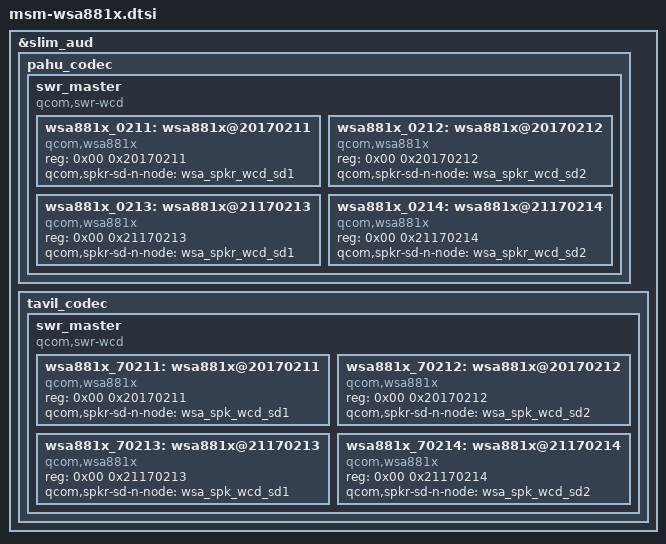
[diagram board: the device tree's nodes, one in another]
// SPDX-License-Identifier: GPL-2.0-only
/*
 * Copyright (c) 2016-2017, The Linux Foundation. All rights reserved.
 */

&slim_aud {
	pahu_codec {
		swr_master {
			compatible = "qcom,swr-wcd";
			#address-cells = <2>;
			#size-cells = <0>;

			wsa881x_0211: wsa881x@20170211 {
				compatible = "qcom,wsa881x";
				reg = <0x00 0x20170211>;
				qcom,spkr-sd-n-node = <&wsa_spkr_wcd_sd1>;
			};

			wsa881x_0212: wsa881x@20170212 {
				compatible = "qcom,wsa881x";
				reg = <0x00 0x20170212>;
				qcom,spkr-sd-n-node = <&wsa_spkr_wcd_sd2>;
			};

			wsa881x_0213: wsa881x@21170213 {
				compatible = "qcom,wsa881x";
				reg = <0x00 0x21170213>;
				qcom,spkr-sd-n-node = <&wsa_spkr_wcd_sd1>;
			};

			wsa881x_0214: wsa881x@21170214 {
				compatible = "qcom,wsa881x";
				reg = <0x00 0x21170214>;
				qcom,spkr-sd-n-node = <&wsa_spkr_wcd_sd2>;
			};
		};
	};

	tavil_codec {
		swr_master {
			compatible = "qcom,swr-wcd";
			#address-cells = <2>;
			#size-cells = <0>;

			wsa881x_70211: wsa881x@20170211 {
				compatible = "qcom,wsa881x";
				reg = <0x00 0x20170211>;
				qcom,spkr-sd-n-node = <&wsa_spk_wcd_sd1>;
			};

			wsa881x_70212: wsa881x@20170212 {
				compatible = "qcom,wsa881x";
				reg = <0x00 0x20170212>;
				qcom,spkr-sd-n-node = <&wsa_spk_wcd_sd2>;
			};

			wsa881x_70213: wsa881x@21170213 {
				compatible = "qcom,wsa881x";
				reg = <0x00 0x21170213>;
				qcom,spkr-sd-n-node = <&wsa_spk_wcd_sd1>;
			};

			wsa881x_70214: wsa881x@21170214 {
				compatible = "qcom,wsa881x";
				reg = <0x00 0x21170214>;
				qcom,spkr-sd-n-node = <&wsa_spk_wcd_sd2>;
			};
		};
	};
};
